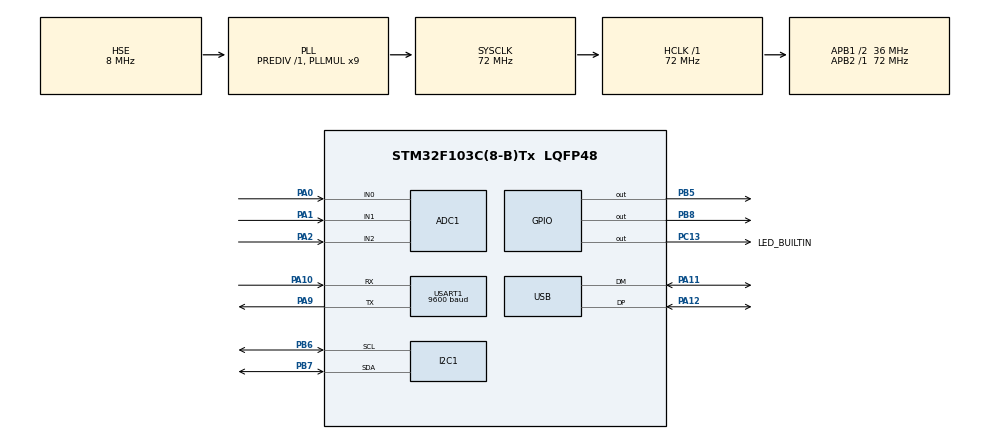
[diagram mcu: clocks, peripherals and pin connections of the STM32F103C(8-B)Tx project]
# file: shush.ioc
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ADC1.Channel-0\#ChannelRegularConversion=ADC_CHANNEL_0
ADC1.NbrOfConversionFlag=1
ADC1.Rank-0\#ChannelRegularConversion=1
ADC1.SamplingTime-0\#ChannelRegularConversion=ADC_SAMPLETIME_1CYCLE_5
ADC1.master=1
I2C1.DutyCycle=I2C_DUTYCYCLE_2
I2C1.I2C_Mode=I2C_Fast
Mcu.Family=STM32F1
Mcu.Name=STM32F103C(8-B)Tx
Mcu.Package=LQFP48
Mcu.UserConstants=TIM1_ARR,(4915-1);TIM1_PSC,(10000-1)
NVIC.PriorityGroup=NVIC_PRIORITYGROUP_4
NVIC.TIM3_IRQn=true\:0\:0\:false\:false\:true\:true\:true\:true
NVIC.USB_LP_CAN1_RX0_IRQn=true\:0\:0\:false\:false\:true\:false\:true\:true
PA0-WKUP.Signal=ADCx_IN0
PA1.Signal=ADCx_IN1
PA10.Mode=Asynchronous
PA10.Signal=USART1_RX
PA11.Mode=Device
PA11.Signal=USB_DM
PA12.Mode=Device
PA12.Signal=USB_DP
PA13.Mode=Serial_Wire
PA13.Signal=SYS_JTMS-SWDIO
PA14.Mode=Serial_Wire
PA14.Signal=SYS_JTCK-SWCLK
PA2.Signal=ADCx_IN2
PA9.Mode=Asynchronous
PA9.Signal=USART1_TX
PB5.Signal=GPIO_Output
PB6.Mode=I2C
PB6.Signal=I2C1_SCL
PB7.Mode=I2C
PB7.Signal=I2C1_SDA
PB8.GPIO_PuPd=GPIO_PULLDOWN
PB8.GPIO_Speed=GPIO_SPEED_FREQ_HIGH
PB8.PinState=GPIO_PIN_SET
PB8.Signal=GPIO_Output
PC13-TAMPER-RTC.GPIO_Label=LED_BUILTIN
PC13-TAMPER-RTC.GPIO_ModeDefaultOutputPP=GPIO_MODE_OUTPUT_OD
PC13-TAMPER-RTC.GPIO_PuPd=GPIO_NOPULL
PC13-TAMPER-RTC.PinState=GPIO_PIN_SET
PC13-TAMPER-RTC.Signal=GPIO_Output
PC14-OSC32_IN.Mode=LSE-External-Oscillator
PC14-OSC32_IN.Signal=RCC_OSC32_IN
PC15-OSC32_OUT.Mode=LSE-External-Oscillator
PC15-OSC32_OUT.Signal=RCC_OSC32_OUT
PD0-OSC_IN.Mode=HSE-External-Oscillator
PD0-OSC_IN.Signal=RCC_OSC_IN
PD1-OSC_OUT.Mode=HSE-External-Oscillator
PD1-OSC_OUT.Signal=RCC_OSC_OUT
ProjectManager.HeapSize=0x200
ProjectManager.StackSize=0x400
ProjectManager.TargetToolchain=STM32CubeIDE
RCC.ADCPresc=RCC_ADCPCLK2_DIV6
RCC.AHBFreq_Value=72000000
RCC.APB1CLKDivider=RCC_HCLK_DIV2
RCC.APB1Freq_Value=36000000
RCC.APB1TimFreq_Value=72000000
RCC.APB2Freq_Value=72000000
RCC.APB2TimFreq_Value=72000000
RCC.HCLKFreq_Value=72000000
RCC.PLLMUL=RCC_PLL_MUL9
RCC.PLLSourceVirtual=RCC_PLLSOURCE_HSE
RCC.SYSCLKFreq_VALUE=72000000
RCC.SYSCLKSource=RCC_SYSCLKSOURCE_PLLCLK
RCC.USBFreq_Value=48000000
RCC.USBPrescaler=RCC_USBCLKSOURCE_PLL_DIV1_5
SH.ADCx_IN0.0=ADC1_IN0,IN0
SH.ADCx_IN1.0=ADC1_IN1,IN1
SH.ADCx_IN2.0=ADC1_IN2,IN2
TIM3.Channel-Output\ Compare1\ No\ Output=TIM_CHANNEL_1
TIM3.Period=TIM1_ARR
TIM3.Prescaler=TIM1_PSC
TIM3.Pulse-Output\ Compare1\ No\ Output=1
TIM3.TIM_MasterOutputTrigger=TIM_TRGO_UPDATE
USART1.BaudRate=9600
USART1.VirtualMode=VM_ASYNC
USB_DEVICE.CLASS_NAME_FS=DFU
USB_DEVICE.VirtualMode=Dfu
USB_DEVICE.VirtualModeFS=Dfu_FS
VP_CRC_VS_CRC.Mode=CRC_Activate
VP_RTC_VS_RTC_Activate.Mode=RTC_Enabled
VP_TIM3_VS_ClockSourceINT.Mode=Internal
VP_TIM3_VS_no_output1.Mode=Output Compare1 No Output
VP_USB_DEVICE_VS_USB_DEVICE_DFU_FS.Mode=DFU_FS
board=custom

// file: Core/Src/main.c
/* USER CODE BEGIN Header */
/**
  ******************************************************************************
  * @file           : main.c
  * @brief          : Main program body
  ******************************************************************************
  * @attention
  *
  * Copyright (c) 2022 STMicroelectronics.
  * All rights reserved.
  *
  * This software is licensed under terms that can be found in the LICENSE file
  * in the root directory of this software component.
  * If no LICENSE file comes with this software, it is provided AS-IS.
  *
  ******************************************************************************
  */
/* USER CODE END Header */
#include "main.h"
#include "usb_device.h"

/* USER CODE BEGIN Includes */
#include "tools.h"
#include "si5351.h"
#include "wspr.h"
#include "transmitter.h"
#include "gps.h"
/* USER CODE END Includes */

 ADC_HandleTypeDef hadc1;

CRC_HandleTypeDef hcrc;

I2C_HandleTypeDef hi2c1;

RTC_HandleTypeDef hrtc;

TIM_HandleTypeDef htim3;

UART_HandleTypeDef huart1;

void SystemClock_Config(void);
static void MX_GPIO_Init(void);
static void MX_ADC1_Init(void);
static void MX_I2C1_Init(void);
static void MX_RTC_Init(void);
static void MX_CRC_Init(void);
static void MX_USART1_UART_Init(void);
static void MX_TIM3_Init(void);

int main(void)
{

  /* MCU Configuration--------------------------------------------------------*/

  /* Reset of all peripherals, Initializes the Flash interface and the Systick. */
  HAL_Init();

  /* Configure the system clock */
  SystemClock_Config();

  /* Initialize all configured peripherals */
  MX_GPIO_Init();
  MX_ADC1_Init();
  MX_I2C1_Init();
  MX_RTC_Init();
  MX_CRC_Init();
  MX_USART1_UART_Init();
  MX_TIM3_Init();
  MX_USB_DEVICE_Init();
  /* USER CODE BEGIN 2 */

  //int i = HAL_I2C_IsDeviceReady(&hi2c1, SI5351_ADDRESS, 10, 1);
  //__NOP();

  si5351_Init(0);
  si5351_EnableOutputs(0);
  HAL_Delay(300);
  char A[1];
  nmeaProcessString(A, 0);

  wsprInit(hzToFreq(28000000.0f));

  wsprStartTx();

  /* USER CODE END 2 */

  /* Infinite loop */
  while (1)
  {

    /* USER CODE BEGIN 3 */
	HAL_GPIO_TogglePin(GPIOC, GPIO_PIN_13);
	HAL_Delay(500);
  }
  /* USER CODE END 3 */
}

void SystemClock_Config(void)
{
  RCC_OscInitTypeDef RCC_OscInitStruct = {0};
  RCC_ClkInitTypeDef RCC_ClkInitStruct = {0};
  RCC_PeriphCLKInitTypeDef PeriphClkInit = {0};

  /** Initializes the RCC Oscillators according to the specified parameters
  * in the RCC_OscInitTypeDef structure.
  */
  RCC_OscInitStruct.OscillatorType = RCC_OSCILLATORTYPE_LSI|RCC_OSCILLATORTYPE_HSE;
  RCC_OscInitStruct.HSEState = RCC_HSE_ON;
  RCC_OscInitStruct.HSEPredivValue = RCC_HSE_PREDIV_DIV1;
  RCC_OscInitStruct.HSIState = RCC_HSI_ON;
  RCC_OscInitStruct.LSIState = RCC_LSI_ON;
  RCC_OscInitStruct.PLL.PLLState = RCC_PLL_ON;
  RCC_OscInitStruct.PLL.PLLSource = RCC_PLLSOURCE_HSE;
  RCC_OscInitStruct.PLL.PLLMUL = RCC_PLL_MUL9;
  if (HAL_RCC_OscConfig(&RCC_OscInitStruct) != HAL_OK)
  {
    Error_Handler();
  }

  /** Initializes the CPU, AHB and APB buses clocks
  */
  RCC_ClkInitStruct.ClockType = RCC_CLOCKTYPE_HCLK|RCC_CLOCKTYPE_SYSCLK
                              |RCC_CLOCKTYPE_PCLK1|RCC_CLOCKTYPE_PCLK2;
  RCC_ClkInitStruct.SYSCLKSource = RCC_SYSCLKSOURCE_PLLCLK;
  RCC_ClkInitStruct.AHBCLKDivider = RCC_SYSCLK_DIV1;
  RCC_ClkInitStruct.APB1CLKDivider = RCC_HCLK_DIV2;
  RCC_ClkInitStruct.APB2CLKDivider = RCC_HCLK_DIV1;

  if (HAL_RCC_ClockConfig(&RCC_ClkInitStruct, FLASH_LATENCY_2) != HAL_OK)
  {
    Error_Handler();
  }
  PeriphClkInit.PeriphClockSelection = RCC_PERIPHCLK_RTC|RCC_PERIPHCLK_ADC
                              |RCC_PERIPHCLK_USB;
  PeriphClkInit.RTCClockSelection = RCC_RTCCLKSOURCE_LSI;
  PeriphClkInit.AdcClockSelection = RCC_ADCPCLK2_DIV6;
  PeriphClkInit.UsbClockSelection = RCC_USBCLKSOURCE_PLL_DIV1_5;
  if (HAL_RCCEx_PeriphCLKConfig(&PeriphClkInit) != HAL_OK)
  {
    Error_Handler();
  }
}

static void MX_ADC1_Init(void)
{

  ADC_ChannelConfTypeDef sConfig = {0};

  /** Common config
  */
  hadc1.Instance = ADC1;
  hadc1.Init.ScanConvMode = ADC_SCAN_DISABLE;
  hadc1.Init.ContinuousConvMode = DISABLE;
  hadc1.Init.DiscontinuousConvMode = DISABLE;
  hadc1.Init.ExternalTrigConv = ADC_SOFTWARE_START;
  hadc1.Init.DataAlign = ADC_DATAALIGN_RIGHT;
  hadc1.Init.NbrOfConversion = 1;
  if (HAL_ADC_Init(&hadc1) != HAL_OK)
  {
    Error_Handler();
  }

  /** Configure Regular Channel
  */
  sConfig.Channel = ADC_CHANNEL_0;
  sConfig.Rank = ADC_REGULAR_RANK_1;
  sConfig.SamplingTime = ADC_SAMPLETIME_1CYCLE_5;
  if (HAL_ADC_ConfigChannel(&hadc1, &sConfig) != HAL_OK)
  {
    Error_Handler();
  }

}

static void MX_CRC_Init(void)
{

  hcrc.Instance = CRC;
  if (HAL_CRC_Init(&hcrc) != HAL_OK)
  {
    Error_Handler();
  }

}

static void MX_I2C1_Init(void)
{

  hi2c1.Instance = I2C1;
  hi2c1.Init.ClockSpeed = 400000;
  hi2c1.Init.DutyCycle = I2C_DUTYCYCLE_2;
  hi2c1.Init.OwnAddress1 = 0;
  hi2c1.Init.AddressingMode = I2C_ADDRESSINGMODE_7BIT;
  hi2c1.Init.DualAddressMode = I2C_DUALADDRESS_DISABLE;
  hi2c1.Init.OwnAddress2 = 0;
  hi2c1.Init.GeneralCallMode = I2C_GENERALCALL_DISABLE;
  hi2c1.Init.NoStretchMode = I2C_NOSTRETCH_DISABLE;
  if (HAL_I2C_Init(&hi2c1) != HAL_OK)
  {
    Error_Handler();
  }

}

static void MX_RTC_Init(void)
{

  /** Initialize RTC Only
  */
  hrtc.Instance = RTC;
  hrtc.Init.AsynchPrediv = RTC_AUTO_1_SECOND;
  hrtc.Init.OutPut = RTC_OUTPUTSOURCE_ALARM;
  if (HAL_RTC_Init(&hrtc) != HAL_OK)
  {
    Error_Handler();
  }

}

static void MX_TIM3_Init(void)
{

  TIM_ClockConfigTypeDef sClockSourceConfig = {0};
  TIM_MasterConfigTypeDef sMasterConfig = {0};
  TIM_OC_InitTypeDef sConfigOC = {0};

  htim3.Instance = TIM3;
  htim3.Init.Prescaler = TIM1_PSC;
  htim3.Init.CounterMode = TIM_COUNTERMODE_UP;
  htim3.Init.Period = TIM1_ARR;
  htim3.Init.ClockDivision = TIM_CLOCKDIVISION_DIV1;
  htim3.Init.AutoReloadPreload = TIM_AUTORELOAD_PRELOAD_DISABLE;
  if (HAL_TIM_Base_Init(&htim3) != HAL_OK)
  {
    Error_Handler();
  }
  sClockSourceConfig.ClockSource = TIM_CLOCKSOURCE_INTERNAL;
  if (HAL_TIM_ConfigClockSource(&htim3, &sClockSourceConfig) != HAL_OK)
  {
    Error_Handler();
  }
  if (HAL_TIM_OC_Init(&htim3) != HAL_OK)
  {
    Error_Handler();
  }
  sMasterConfig.MasterOutputTrigger = TIM_TRGO_UPDATE;
  sMasterConfig.MasterSlaveMode = TIM_MASTERSLAVEMODE_DISABLE;
  if (HAL_TIMEx_MasterConfigSynchronization(&htim3, &sMasterConfig) != HAL_OK)
  {
    Error_Handler();
  }
  sConfigOC.OCMode = TIM_OCMODE_TIMING;
  sConfigOC.Pulse = 1;
  sConfigOC.OCPolarity = TIM_OCPOLARITY_HIGH;
  sConfigOC.OCFastMode = TIM_OCFAST_DISABLE;
  if (HAL_TIM_OC_ConfigChannel(&htim3, &sConfigOC, TIM_CHANNEL_1) != HAL_OK)
  {
    Error_Handler();
  }

}

static void MX_USART1_UART_Init(void)
{

  huart1.Instance = USART1;
  huart1.Init.BaudRate = 9600;
  huart1.Init.WordLength = UART_WORDLENGTH_8B;
  huart1.Init.StopBits = UART_STOPBITS_1;
  huart1.Init.Parity = UART_PARITY_NONE;
  huart1.Init.Mode = UART_MODE_TX_RX;
  huart1.Init.HwFlowCtl = UART_HWCONTROL_NONE;
  huart1.Init.OverSampling = UART_OVERSAMPLING_16;
  if (HAL_UART_Init(&huart1) != HAL_OK)
  {
    Error_Handler();
  }

}

static void MX_GPIO_Init(void)
{
  GPIO_InitTypeDef GPIO_InitStruct = {0};

  /* GPIO Ports Clock Enable */
  __HAL_RCC_GPIOC_CLK_ENABLE();
  __HAL_RCC_GPIOD_CLK_ENABLE();
  __HAL_RCC_GPIOA_CLK_ENABLE();
  __HAL_RCC_GPIOB_CLK_ENABLE();

  /*Configure GPIO pin Output Level */
  HAL_GPIO_WritePin(LED_BUILTIN_GPIO_Port, LED_BUILTIN_Pin, GPIO_PIN_SET);

  /*Configure GPIO pin Output Level */
  HAL_GPIO_WritePin(GPIOB, GPIO_PIN_5, GPIO_PIN_RESET);

  /*Configure GPIO pin Output Level */
  HAL_GPIO_WritePin(GPIOB, GPIO_PIN_8, GPIO_PIN_SET);

  /*Configure GPIO pin : LED_BUILTIN_Pin */
  GPIO_InitStruct.Pin = LED_BUILTIN_Pin;
  GPIO_InitStruct.Mode = GPIO_MODE_OUTPUT_OD;
  GPIO_InitStruct.Pull = GPIO_NOPULL;
  GPIO_InitStruct.Speed = GPIO_SPEED_FREQ_LOW;
  HAL_GPIO_Init(LED_BUILTIN_GPIO_Port, &GPIO_InitStruct);

  /*Configure GPIO pin : PB5 */
  GPIO_InitStruct.Pin = GPIO_PIN_5;
  GPIO_InitStruct.Mode = GPIO_MODE_OUTPUT_PP;
  GPIO_InitStruct.Pull = GPIO_NOPULL;
  GPIO_InitStruct.Speed = GPIO_SPEED_FREQ_LOW;
  HAL_GPIO_Init(GPIOB, &GPIO_InitStruct);

  /*Configure GPIO pin : PB8 */
  GPIO_InitStruct.Pin = GPIO_PIN_8;
  GPIO_InitStruct.Mode = GPIO_MODE_OUTPUT_PP;
  GPIO_InitStruct.Pull = GPIO_PULLDOWN;
  GPIO_InitStruct.Speed = GPIO_SPEED_FREQ_HIGH;
  HAL_GPIO_Init(GPIOB, &GPIO_InitStruct);

}

void Error_Handler(void)
{
  __disable_irq();
  while (1)
  {
  }
}
